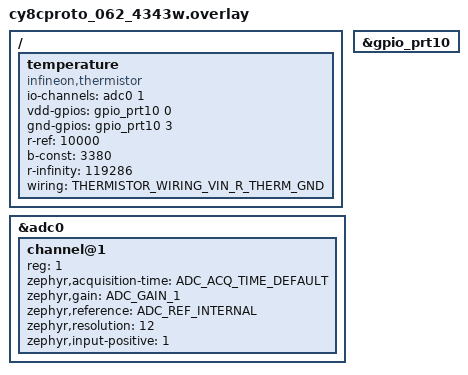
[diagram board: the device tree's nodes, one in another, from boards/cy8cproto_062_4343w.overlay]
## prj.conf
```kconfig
CONFIG_ZTEST=y
CONFIG_ZTEST_NEW_API=y
CONFIG_TEST_USERSPACE=y
CONFIG_LOG=y
CONFIG_SENSOR=y
CONFIG_GPIO=y
CONFIG_ADC=y
CONFIG_CBPRINTF_FP_SUPPORT=y
CONFIG_NEWLIB_LIBC=y
```

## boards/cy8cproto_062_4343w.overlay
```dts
/*
 * SPDX-License-Identifier: Apache-2.0
 *
 * Copyright (c) 2023 Cypress Semiconductor Corporation (an Infineon company) or
 * an affiliate of Cypress Semiconductor Corporation
 */

#include <zephyr/dt-bindings/adc/adc.h>
#include <../drivers/sensor/thermistor/thermistor.h>

/ {
	temperature {
		compatible = "infineon,thermistor";
		io-channels = <&adc0 1>;
		vdd-gpios = <&gpio_prt10 0 GPIO_ACTIVE_HIGH>;
		gnd-gpios = <&gpio_prt10 3 GPIO_ACTIVE_HIGH>;
		r-ref = <10000>;
		b-const = <3380>;
		r-infinity = <119286>;
		wiring = <THERMISTOR_WIRING_VIN_R_THERM_GND>;
	};
};

&adc0 {
	status = "okay";
	#address-cells = <1>;
	#size-cells = <0>;

	channel@1 {
		reg = <1>;
		zephyr,acquisition-time = <ADC_ACQ_TIME_DEFAULT>;
		zephyr,gain = "ADC_GAIN_1";
		zephyr,reference = "ADC_REF_INTERNAL";
		zephyr,resolution = <12>;
		zephyr,input-positive = <1>;   /* P10.1 */
	};
};

&gpio_prt10 {
	status = "okay";
};
```

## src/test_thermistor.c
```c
/*
 * Copyright (c) 2023 Cypress Semiconductor Corporation (an Infineon company) or
 * an affiliate of Cypress Semiconductor Corporation
 *
 * SPDX-License-Identifier: Apache-2.0
 */

#include <zephyr/drivers/sensor.h>
#include <zephyr/kernel.h>
#include <zephyr/ztest.h>

#define LO_CELSIUS (15)
#define HI_CELSIUS (30)

void test_thermistor_read(void)
{
	const struct device *const dev = DEVICE_DT_GET_ONE(infineon_thermistor);
	struct sensor_value value;
	char invalid_temp_msg[40];
	double temp_celsius;

	zassert_true(device_is_ready(dev), "Thermistor is not ready");

	zassert_ok(sensor_sample_fetch(dev), "Failed to fetch sample");
	zassert_ok(sensor_channel_get(dev, SENSOR_CHAN_AMBIENT_TEMP, &value),
		   "Failed to get sensor data");

	temp_celsius = sensor_value_to_double(&value);
	sprintf(invalid_temp_msg, "Invalid temperature: %.2f C", temp_celsius);
	zassert_true((temp_celsius > LO_CELSIUS) && (temp_celsius < HI_CELSIUS), invalid_temp_msg);
}

void test_thermistor_bad_chan(void)
{
	const struct device *const dev = DEVICE_DT_GET_ONE(infineon_thermistor);
	struct sensor_value value;

	zassert_true(device_is_ready(dev), "Thermistor is not ready");

	zassert_ok(sensor_sample_fetch(dev), "Failed to fetch sample");
	zassert_true(sensor_channel_get(dev, SENSOR_CHAN_HUMIDITY, &value) != 0,
		     "Invalid sensor channel accepted");
}

ZTEST(thermistor, test_thermistor_read) {
	test_thermistor_read();
}

ZTEST(thermistor, test_thermistor_bad_chan) {
	test_thermistor_bad_chan();
}

ZTEST_SUITE(thermistor, NULL, NULL, NULL, NULL, NULL);
```
